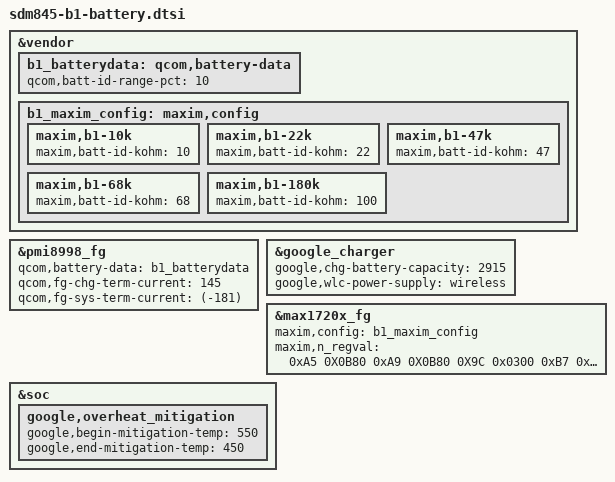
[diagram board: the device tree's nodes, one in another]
/* Copyright (c) 2017, The Linux Foundation. All rights reserved.
 *
 * This program is free software; you can redistribute it and/or modify
 * it under the terms of the GNU General Public License version 2 and
 * only version 2 as published by the Free Software Foundation.
 *
 * This program is distributed in the hope that it will be useful,
 * but WITHOUT ANY WARRANTY; without even the implied warranty of
 * MERCHANTABILITY or FITNESS FOR A PARTICULAR PURPOSE.  See the
 * GNU General Public License for more details.
 */

&vendor {
	b1_batterydata: qcom,battery-data {
		qcom,batt-id-range-pct = <10>;
		/* Desay using Lishen cell - 10k
		 * Sunwoda using Lishen cell - 22k
		 * Desay using ATL cell - 47k
		 * Sunwoda using ATL cell - 68k
		 * Sunwoda using Liwinon cell - 100k
		 */
		#include "batterydata-qcom-b1-10k.dtsi"
		#include "batterydata-qcom-b1-22k.dtsi"
		#include "batterydata-qcom-b1-47k.dtsi"
		#include "batterydata-qcom-b1-68k.dtsi"
		#include "batterydata-qcom-b1-100k.dtsi"
	};
};

&pmi8998_fg {
	qcom,battery-data = <&b1_batterydata>;
	qcom,fg-chg-term-current = <145>;
	qcom,fg-sys-term-current = <(-181)>;
};

&google_charger {
	google,chg-battery-capacity = <2915>;
	google,wlc-power-supply = "wireless";
};

&vendor {
	b1_maxim_config: maxim,config {
		maxim,b1-10k {
			maxim,batt-id-kohm = <10>;
#include "batterydata-maxim-b1-10k.dtsi"
		};
		maxim,b1-22k {
			maxim,batt-id-kohm = <22>;
#include "batterydata-maxim-b1-22k.dtsi"
		};
		maxim,b1-47k {
			maxim,batt-id-kohm = <47>;
#include "batterydata-maxim-b1-47k.dtsi"
		};
		maxim,b1-68k {
			maxim,batt-id-kohm = <68>;
#include "batterydata-maxim-b1-68k.dtsi"
		};
		maxim,b1-180k {
			maxim,batt-id-kohm = <100>;
#include "batterydata-maxim-b1-100k.dtsi"
		};
	};
};

&max1720x_fg {
	maxim,config = <&b1_maxim_config>;
	maxim,n_regval =  /bits/ 16 <
	    0xA5 0X0B80 /* nFullCapNom = 2944 mAh */
	    0xA9 0X0B80 /* nFullCapRep = 2944 mAh */
	    0X9C 0x0300 /* nIChgTerm = 240 mA */
	    0xB7 0x2FC1	/* NConvgCfg: VoltLowOff = 620 mV */
	    0x9F 0x2602 /* nLearnCfg */
	    /* TAlrtEn required to route dSOC to ALRT1 pin */
	    0xB0 0x7217 /* nConfig: SS TS VS Tex Aen dSOCen TAlrtEn */
	    0xC0 0xFF00	/* nVAlrtTh: disabled */
	    0xC1 0x7F80 /* nTAlrtTh: disabled */
	    0xC2 0xFF00	/* nSAlrtTh: disabled */
	    0x9D 0x0EB4 /* nFilterCfg: Volt = 90 sec */
	    0xC6 0x5A05 /* nFullSOCThr = 90% */
	    0XB8 0xCDD0 /* nNVCfg0 */
	>;
};

&soc {
	google,overheat_mitigation {
		google,begin-mitigation-temp = <550>;
		google,end-mitigation-temp = <450>;
	};
};
